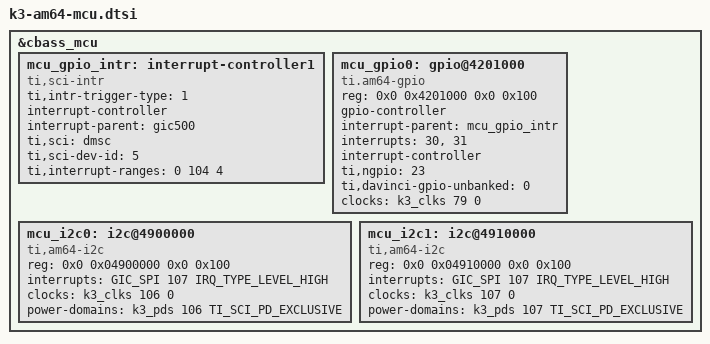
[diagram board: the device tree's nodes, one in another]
// SPDX-License-Identifier: GPL-2.0
/*
 * Device Tree Source for AM64 SoC Family MCU Domain peripherals
 *
 * Copyright (C) 2020 Texas Instruments Incorporated - https://www.ti.com/
 */

&cbass_mcu {

	mcu_gpio_intr: interrupt-controller1 {
		compatible = "ti,sci-intr";
		ti,intr-trigger-type = <1>;
		interrupt-controller;
		interrupt-parent = <&gic500>;
		#interrupt-cells = <1>;
		ti,sci = <&dmsc>;
		ti,sci-dev-id = <5>;
		ti,interrupt-ranges = <0 104 4>;
	};

	mcu_gpio0: gpio@4201000 {
		compatible = "ti.am64-gpio", "keystone-gpio";
		reg = <0x0 0x4201000 0x0 0x100>;
		gpio-controller;
		#gpio-cells = <2>;
		interrupt-parent = <&mcu_gpio_intr>;
		interrupts = <30>, <31>;
		interrupt-controller;
		#interrupt-cells = <2>;
		ti,ngpio = <23>;
		ti,davinci-gpio-unbanked = <0>;
		clocks = <&k3_clks 79 0>;
		clock-names = "gpio";
	};

	mcu_i2c0: i2c@4900000 {
		compatible = "ti,am64-i2c", "ti,omap4-i2c";
		reg = <0x0 0x04900000 0x0 0x100>;
		interrupts = <GIC_SPI 107 IRQ_TYPE_LEVEL_HIGH>;
		#address-cells = <1>;
		#size-cells = <0>;
		clock-names = "fck";
		clocks = <&k3_clks 106 0>;
		power-domains = <&k3_pds 106 TI_SCI_PD_EXCLUSIVE>;
	};

	mcu_i2c1: i2c@4910000 {
		compatible = "ti,am64-i2c", "ti, omap4-i2c";
		reg = <0x0 0x04910000 0x0 0x100>;
		interrupts = <GIC_SPI 107 IRQ_TYPE_LEVEL_HIGH>;
		#address-cells = <1>;
		#size-cells = <0>;
		clock-names = "fck";
		clocks = <&k3_clks 107 0>;
		power-domains = <&k3_pds 107 TI_SCI_PD_EXCLUSIVE>;
	};
};
